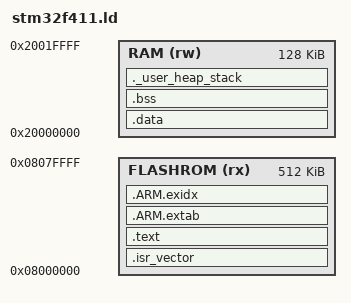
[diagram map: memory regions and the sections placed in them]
MEMORY
{
  FLASHROM (rx)  : ORIGIN = 0x08000000, LENGTH = 512K
  RAM      (rw)  : ORIGIN = 0x20000000, LENGTH = 128K
}

_estack = ORIGIN(RAM) + LENGTH(RAM);
_Min_Stack_Size = 0x400;

ENTRY(Reset_Handler)

SECTIONS
{
  .isr_vector :
  {
    . = ALIGN(4);
    KEEP(*(.isr_vector))
    . = ALIGN(4);
  } >FLASHROM

  .text :
  {
    . = ALIGN(4);
    *(.text)
    *(.text*)
    *(.rodata)
    *(.rodata*)
    . = ALIGN(4);
    _etext = .;
  } >FLASHROM

  .ARM.extab :
  {
    . = ALIGN(4);
    *(.ARM.extab*)
    . = ALIGN(4);
  } >FLASHROM

  .ARM.exidx :
  {
    __exidx_start = .;
    *(.ARM.exidx*)
    __exidx_end = .;
    . = ALIGN(4);
  } >FLASHROM

  _sidata = .;

  .data : AT(_sidata)
  {
    . = ALIGN(4);
    _sdata = .;
    *(.data)
    *(.data*)
    . = ALIGN(4);
    _edata = .;
  } >RAM

  .bss :
  {
    . = ALIGN(4);
    _sbss = .;
    *(.bss)
    *(COMMON)
    . = ALIGN(4);
    _ebss = .;
  } >RAM

  ._user_heap_stack :
  {
    . = ALIGN(8);
    . = . + _Min_Stack_Size;
    . = ALIGN(8);
  } >RAM
}
